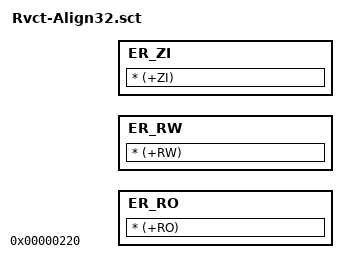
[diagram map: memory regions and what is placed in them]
/** @file

  Copyright (c) 2015, Linaro Ltd. All rights reserved.<BR>

  This program and the accompanying materials are licensed and made available under
  the terms and conditions of the BSD License that accompanies this distribution.
  The full text of the license may be found at
  http://opensource.org/licenses/bsd-license.php.

  THE PROGRAM IS DISTRIBUTED UNDER THE BSD LICENSE ON AN "AS IS" BASIS,
  WITHOUT WARRANTIES OR REPRESENTATIONS OF ANY KIND, EITHER EXPRESS OR IMPLIED.

**/

REGION 0x220 RELOC {
  ER_RO +0 ALIGN 32 {
    * (+RO)
  }
  ER_RW +0 ALIGN 32 {
    * (+RW)
  }
  ER_ZI +0 {
    * (+ZI)
  }
}
